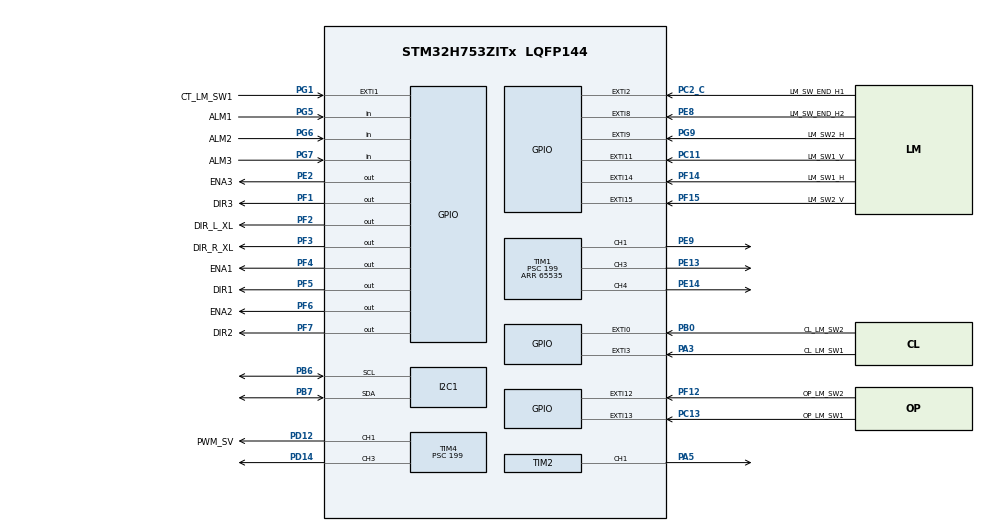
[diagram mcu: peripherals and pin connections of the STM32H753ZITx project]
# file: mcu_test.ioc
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CORTEX_M7.CPU_DCache=Disabled
CORTEX_M7.CPU_ICache=Disabled
CORTEX_M7.MPU_Control=__NULL
CORTEX_M7.default_mode_Activation=1
I2C1.Timing=0x10C0ECFF
Mcu.Family=STM32H7
Mcu.Name=STM32H753ZITx
Mcu.Package=LQFP144
NVIC.EXTI0_IRQn=true\:0\:0\:false\:false\:true\:true\:true\:true
NVIC.EXTI15_10_IRQn=true\:0\:0\:false\:false\:true\:true\:true\:true
NVIC.EXTI1_IRQn=true\:0\:0\:false\:false\:true\:true\:true\:true
NVIC.EXTI2_IRQn=true\:0\:0\:false\:false\:true\:true\:true\:true
NVIC.EXTI3_IRQn=true\:0\:0\:false\:false\:true\:true\:true\:true
NVIC.EXTI9_5_IRQn=true\:0\:0\:false\:false\:true\:true\:true\:true
NVIC.PriorityGroup=NVIC_PRIORITYGROUP_4
NVIC.TIM1_UP_IRQn=true\:0\:0\:false\:false\:true\:true\:true\:true
PA3.GPIO_Label=CL_LM_SW1
PA3.GPIO_ModeDefaultEXTI=GPIO_MODE_IT_RISING_FALLING
PA3.GPIO_PuPd=GPIO_PULLUP
PA3.Signal=GPXTI3
PA5.GPIO_ModeDefaultPP=GPIO_MODE_AF_PP
PA5.GPIO_PuPd=GPIO_PULLDOWN
PA5.Signal=S_TIM2_CH1_ETR
PB0.GPIO_Label=CL_LM_SW2
PB0.GPIO_ModeDefaultEXTI=GPIO_MODE_IT_RISING_FALLING
PB0.GPIO_PuPd=GPIO_PULLUP
PB0.Signal=GPXTI0
PB6.GPIO_Mode=GPIO_MODE_AF_OD
PB6.GPIO_Pu=GPIO_PULLUP
PB6.Mode=I2C
PB6.Signal=I2C1_SCL
PB7.GPIO_Mode=GPIO_MODE_AF_OD
PB7.GPIO_Pu=GPIO_PULLUP
PB7.Mode=I2C
PB7.Signal=I2C1_SDA
PC11.GPIO_Label=LM_SW1_V
PC11.GPIO_ModeDefaultEXTI=GPIO_MODE_IT_RISING_FALLING
PC11.GPIO_PuPd=GPIO_PULLUP
PC11.Signal=GPXTI11
PC13.GPIO_Label=OP_LM_SW1
PC13.GPIO_ModeDefaultEXTI=GPIO_MODE_IT_RISING_FALLING
PC13.GPIO_PuPd=GPIO_PULLUP
PC13.Signal=GPXTI13
PC14-OSC32_IN\ (OSC32_IN).Signal=RCC_OSC32_IN
PC15-OSC32_OUT\ (OSC32_OUT).Signal=RCC_OSC32_OUT
PC2_C.GPIO_Label=LM_SW_END_H1
PC2_C.GPIO_ModeDefaultEXTI=GPIO_MODE_IT_RISING_FALLING
PC2_C.GPIO_PuPd=GPIO_PULLUP
PC2_C.Signal=GPXTI2
PD12.GPIO_Label=PWM_SV
PD12.GPIO_PuPd=GPIO_PULLDOWN
PD12.Signal=S_TIM4_CH1
PD14.GPIO_PuPd=GPIO_PULLDOWN
PD14.Signal=S_TIM4_CH3
PD8.GPIO_Label=STLINK_RX
PD8.Signal=USART3_TX
PD9.GPIO_Label=STLINK_TX
PD9.Signal=USART3_RX
PE13.Signal=S_TIM1_CH3
PE14.Signal=S_TIM1_CH4
PE2.GPIO_Label=ENA3
PE2.PinState=GPIO_PIN_SET
PE2.Signal=GPIO_Output
PE8.GPIO_Label=LM_SW_END_H2
PE8.GPIO_ModeDefaultEXTI=GPIO_MODE_IT_RISING_FALLING
PE8.GPIO_PuPd=GPIO_PULLUP
PE8.Signal=GPXTI8
PE9.Signal=S_TIM1_CH1
PF1.GPIO_Label=DIR3
PF1.Signal=GPIO_Output
PF12.GPIO_Label=OP_LM_SW2
PF12.GPIO_ModeDefaultEXTI=GPIO_MODE_IT_RISING_FALLING
PF12.GPIO_PuPd=GPIO_PULLUP
PF12.Signal=GPXTI12
PF14.GPIO_Label=LM_SW1_H
PF14.GPIO_ModeDefaultEXTI=GPIO_MODE_IT_RISING_FALLING
PF14.GPIO_PuPd=GPIO_PULLUP
PF14.Signal=GPXTI14
PF15.GPIO_Label=LM_SW2_V
PF15.GPIO_ModeDefaultEXTI=GPIO_MODE_IT_RISING_FALLING
PF15.GPIO_PuPd=GPIO_PULLUP
PF15.Signal=GPXTI15
PF2.GPIO_Label=DIR_L_XL
PF2.GPIO_ModeDefaultOutputPP=GPIO_MODE_OUTPUT_PP
PF2.GPIO_PuPd=GPIO_NOPULL
PF2.Signal=GPIO_Output
PF3.GPIO_Label=DIR_R_XL
PF3.GPIO_ModeDefaultOutputPP=GPIO_MODE_OUTPUT_PP
PF3.GPIO_PuPd=GPIO_NOPULL
PF3.PinState=GPIO_PIN_RESET
PF3.Signal=GPIO_Output
PF4.GPIO_Label=ENA1
PF4.GPIO_ModeDefaultOutputPP=GPIO_MODE_OUTPUT_PP
PF4.PinState=GPIO_PIN_SET
PF4.Signal=GPIO_Output
PF5.GPIO_Label=DIR1
PF5.Signal=GPIO_Output
PF6.GPIO_Label=ENA2
PF6.PinState=GPIO_PIN_SET
PF6.Signal=GPIO_Output
PF7.GPIO_Label=DIR2
PF7.PinState=GPIO_PIN_RESET
PF7.Signal=GPIO_Output
PG1.GPIO_Label=CT_LM_SW1
PG1.GPIO_ModeDefaultEXTI=GPIO_MODE_IT_RISING_FALLING
PG1.GPIO_PuPd=GPIO_PULLUP
PG1.Signal=GPXTI1
PG5.GPIO_Label=ALM1
PG5.GPIO_PuPd=GPIO_PULLUP
PG5.Signal=GPIO_Input
PG6.GPIO_Label=ALM2
PG6.GPIO_PuPd=GPIO_PULLUP
PG6.Signal=GPIO_Input
PG7.GPIO_Label=ALM3
PG7.GPIO_PuPd=GPIO_PULLUP
PG7.Signal=GPIO_Input
PG9.GPIO_Label=LM_SW2_H
PG9.GPIO_ModeDefaultEXTI=GPIO_MODE_IT_RISING_FALLING
PG9.GPIO_PuPd=GPIO_PULLUP
PG9.Signal=GPXTI9
PH0-OSC_IN\ (PH0).Signal=RCC_OSC_IN
PH1-OSC_OUT\ (PH1).Signal=RCC_OSC_OUT
ProjectManager.HeapSize=0x200
ProjectManager.StackSize=0x400
ProjectManager.TargetToolchain=CMake
RCC.ADCFreq_Value=129000000
RCC.APB1Freq_Value=100000000
RCC.APB2Freq_Value=100000000
RCC.APB3Freq_Value=100000000
RCC.APB4Freq_Value=100000000
RCC.CortexFreq_Value=400000000
RCC.D1PPRE=RCC_APB3_DIV2
RCC.D2PPRE1=RCC_APB1_DIV2
RCC.D2PPRE2=RCC_APB2_DIV2
RCC.D3PPRE=RCC_APB4_DIV2
RCC.DIVM1=8
RCC.DIVN1=100
RCC.DIVQ1=4
RCC.HCLKFreq_Value=200000000
RCC.HPRE=RCC_HCLK_DIV2
RCC.HSE_VALUE=8000000
RCC.PLLFRACN=0
RCC.PWR_Regulator_Voltage_Scale=PWR_REGULATOR_VOLTAGE_SCALE1
RCC.SYSCLKFreq_VALUE=400000000
RCC.SYSCLKSource=RCC_SYSCLKSOURCE_PLLCLK
RCC.USBFreq_Value=200000000
SH.S_TIM1_CH1.0=TIM1_CH1,PWM Generation1 CH1
SH.S_TIM1_CH3.0=TIM1_CH3,PWM Generation3 CH3
SH.S_TIM1_CH4.0=TIM1_CH4,PWM Generation4 CH4
SH.S_TIM2_CH1_ETR.0=TIM2_CH1,PWM Generation1 CH1
SH.S_TIM4_CH1.0=TIM4_CH1,PWM Generation1 CH1
SH.S_TIM4_CH3.0=TIM4_CH3,PWM Generation3 CH3
TIM1.Channel-PWM\ Generation1\ CH1=TIM_CHANNEL_1
TIM1.Channel-PWM\ Generation3\ CH3=TIM_CHANNEL_3
TIM1.Channel-PWM\ Generation4\ CH4=TIM_CHANNEL_4
TIM1.Period=65535
TIM1.Prescaler=199
TIM2.Channel-PWM\ Generation1\ CH1=TIM_CHANNEL_1
TIM2.Period=3002
TIM2.Prescaler=199
TIM4.Channel-PWM\ Generation1\ CH1=TIM_CHANNEL_1
TIM4.Channel-PWM\ Generation3\ CH3=TIM_CHANNEL_3
TIM4.Period=3002
TIM4.Prescaler=199
TIM4.Pulse-PWM\ Generation1\ CH1=1900
VP_MEMORYMAP_VS_MEMORYMAP.Mode=CurAppReg
VP_TIM1_VS_ClockSourceINT.Mode=Internal
VP_TIM2_VS_ClockSourceINT.Mode=Internal
VP_TIM4_VS_ClockSourceINT.Mode=Internal
board=NUCLEO-H753ZI

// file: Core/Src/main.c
/* USER CODE BEGIN Header */
/**
  ******************************************************************************
  * @file           : main.c
  * @brief          : Main program body
  ******************************************************************************
  * @attention
  *
  * Copyright (c) 2026 STMicroelectronics.
  * All rights reserved.
  *
  * This software is licensed under terms that can be found in the LICENSE file
  * in the root directory of this software component.
  * If no LICENSE file comes with this software, it is provided AS-IS.
  *
  ******************************************************************************
  */
/* USER CODE END Header */
#include "main.h"

/* USER CODE BEGIN Includes */
#include "app.h"
/* USER CODE END Includes */

I2C_HandleTypeDef hi2c1;

TIM_HandleTypeDef htim1;
TIM_HandleTypeDef htim2;
TIM_HandleTypeDef htim4;

void SystemClock_Config(void);
static void MX_GPIO_Init(void);
static void MX_TIM4_Init(void);
static void MX_TIM1_Init(void);
static void MX_TIM2_Init(void);
static void MX_I2C1_Init(void);

int main(void)
{

  /* MCU Configuration--------------------------------------------------------*/

  /* Reset of all peripherals, Initializes the Flash interface and the Systick. */
  HAL_Init();

  /* Configure the system clock */
  SystemClock_Config();

  /* Initialize all configured peripherals */
  MX_GPIO_Init();
  MX_TIM4_Init();
  MX_TIM1_Init();
  MX_TIM2_Init();
  MX_I2C1_Init();
  /* USER CODE BEGIN 2 */
  App_Init();
  /* USER CODE END 2 */

  /* Infinite loop */
  while (1)
  {

    /* USER CODE BEGIN 3 */
    App_Poll();
  }
  /* USER CODE END 3 */
}

void SystemClock_Config(void)
{
  RCC_OscInitTypeDef RCC_OscInitStruct = {0};
  RCC_ClkInitTypeDef RCC_ClkInitStruct = {0};

  /** Supply configuration update enable
  */
  HAL_PWREx_ConfigSupply(PWR_LDO_SUPPLY);

  /** Configure the main internal regulator output voltage
  */
  __HAL_PWR_VOLTAGESCALING_CONFIG(PWR_REGULATOR_VOLTAGE_SCALE1);

  while(!__HAL_PWR_GET_FLAG(PWR_FLAG_VOSRDY)) {}

  /** Initializes the RCC Oscillators according to the specified parameters
  * in the RCC_OscInitTypeDef structure.
  */
  RCC_OscInitStruct.OscillatorType = RCC_OSCILLATORTYPE_HSI;
  RCC_OscInitStruct.HSIState = RCC_HSI_DIV1;
  RCC_OscInitStruct.HSICalibrationValue = RCC_HSICALIBRATION_DEFAULT;
  RCC_OscInitStruct.PLL.PLLState = RCC_PLL_ON;
  RCC_OscInitStruct.PLL.PLLSource = RCC_PLLSOURCE_HSI;
  RCC_OscInitStruct.PLL.PLLM = 8;
  RCC_OscInitStruct.PLL.PLLN = 100;
  RCC_OscInitStruct.PLL.PLLP = 2;
  RCC_OscInitStruct.PLL.PLLQ = 4;
  RCC_OscInitStruct.PLL.PLLR = 2;
  RCC_OscInitStruct.PLL.PLLRGE = RCC_PLL1VCIRANGE_3;
  RCC_OscInitStruct.PLL.PLLVCOSEL = RCC_PLL1VCOWIDE;
  RCC_OscInitStruct.PLL.PLLFRACN = 0;
  if (HAL_RCC_OscConfig(&RCC_OscInitStruct) != HAL_OK)
  {
    Error_Handler();
  }

  /** Initializes the CPU, AHB and APB buses clocks
  */
  RCC_ClkInitStruct.ClockType = RCC_CLOCKTYPE_HCLK|RCC_CLOCKTYPE_SYSCLK
                              |RCC_CLOCKTYPE_PCLK1|RCC_CLOCKTYPE_PCLK2
                              |RCC_CLOCKTYPE_D3PCLK1|RCC_CLOCKTYPE_D1PCLK1;
  RCC_ClkInitStruct.SYSCLKSource = RCC_SYSCLKSOURCE_PLLCLK;
  RCC_ClkInitStruct.SYSCLKDivider = RCC_SYSCLK_DIV1;
  RCC_ClkInitStruct.AHBCLKDivider = RCC_HCLK_DIV2;
  RCC_ClkInitStruct.APB3CLKDivider = RCC_APB3_DIV2;
  RCC_ClkInitStruct.APB1CLKDivider = RCC_APB1_DIV2;
  RCC_ClkInitStruct.APB2CLKDivider = RCC_APB2_DIV2;
  RCC_ClkInitStruct.APB4CLKDivider = RCC_APB4_DIV2;

  if (HAL_RCC_ClockConfig(&RCC_ClkInitStruct, FLASH_LATENCY_2) != HAL_OK)
  {
    Error_Handler();
  }
}

static void MX_I2C1_Init(void)
{

  hi2c1.Instance = I2C1;
  hi2c1.Init.Timing = 0x10C0ECFF;
  hi2c1.Init.OwnAddress1 = 0;
  hi2c1.Init.AddressingMode = I2C_ADDRESSINGMODE_7BIT;
  hi2c1.Init.DualAddressMode = I2C_DUALADDRESS_DISABLE;
  hi2c1.Init.OwnAddress2 = 0;
  hi2c1.Init.OwnAddress2Masks = I2C_OA2_NOMASK;
  hi2c1.Init.GeneralCallMode = I2C_GENERALCALL_DISABLE;
  hi2c1.Init.NoStretchMode = I2C_NOSTRETCH_DISABLE;
  if (HAL_I2C_Init(&hi2c1) != HAL_OK)
  {
    Error_Handler();
  }

  /** Configure Analogue filter
  */
  if (HAL_I2CEx_ConfigAnalogFilter(&hi2c1, I2C_ANALOGFILTER_ENABLE) != HAL_OK)
  {
    Error_Handler();
  }

  /** Configure Digital filter
  */
  if (HAL_I2CEx_ConfigDigitalFilter(&hi2c1, 0) != HAL_OK)
  {
    Error_Handler();
  }

}

static void MX_TIM1_Init(void)
{

  TIM_ClockConfigTypeDef sClockSourceConfig = {0};
  TIM_MasterConfigTypeDef sMasterConfig = {0};
  TIM_OC_InitTypeDef sConfigOC = {0};
  TIM_BreakDeadTimeConfigTypeDef sBreakDeadTimeConfig = {0};

  htim1.Instance = TIM1;
  htim1.Init.Prescaler = 199;
  htim1.Init.CounterMode = TIM_COUNTERMODE_UP;
  htim1.Init.Period = 65535;
  htim1.Init.ClockDivision = TIM_CLOCKDIVISION_DIV1;
  htim1.Init.RepetitionCounter = 0;
  htim1.Init.AutoReloadPreload = TIM_AUTORELOAD_PRELOAD_DISABLE;
  if (HAL_TIM_Base_Init(&htim1) != HAL_OK)
  {
    Error_Handler();
  }
  sClockSourceConfig.ClockSource = TIM_CLOCKSOURCE_INTERNAL;
  if (HAL_TIM_ConfigClockSource(&htim1, &sClockSourceConfig) != HAL_OK)
  {
    Error_Handler();
  }
  if (HAL_TIM_PWM_Init(&htim1) != HAL_OK)
  {
    Error_Handler();
  }
  sMasterConfig.MasterOutputTrigger = TIM_TRGO_RESET;
  sMasterConfig.MasterOutputTrigger2 = TIM_TRGO2_RESET;
  sMasterConfig.MasterSlaveMode = TIM_MASTERSLAVEMODE_DISABLE;
  if (HAL_TIMEx_MasterConfigSynchronization(&htim1, &sMasterConfig) != HAL_OK)
  {
    Error_Handler();
  }
  sConfigOC.OCMode = TIM_OCMODE_PWM1;
  sConfigOC.Pulse = 0;
  sConfigOC.OCPolarity = TIM_OCPOLARITY_HIGH;
  sConfigOC.OCNPolarity = TIM_OCNPOLARITY_HIGH;
  sConfigOC.OCFastMode = TIM_OCFAST_DISABLE;
  sConfigOC.OCIdleState = TIM_OCIDLESTATE_RESET;
  sConfigOC.OCNIdleState = TIM_OCNIDLESTATE_RESET;
  if (HAL_TIM_PWM_ConfigChannel(&htim1, &sConfigOC, TIM_CHANNEL_1) != HAL_OK)
  {
    Error_Handler();
  }
  if (HAL_TIM_PWM_ConfigChannel(&htim1, &sConfigOC, TIM_CHANNEL_3) != HAL_OK)
  {
    Error_Handler();
  }
  if (HAL_TIM_PWM_ConfigChannel(&htim1, &sConfigOC, TIM_CHANNEL_4) != HAL_OK)
  {
    Error_Handler();
  }
  sBreakDeadTimeConfig.OffStateRunMode = TIM_OSSR_DISABLE;
  sBreakDeadTimeConfig.OffStateIDLEMode = TIM_OSSI_DISABLE;
  sBreakDeadTimeConfig.LockLevel = TIM_LOCKLEVEL_OFF;
  sBreakDeadTimeConfig.DeadTime = 0;
  sBreakDeadTimeConfig.BreakState = TIM_BREAK_DISABLE;
  sBreakDeadTimeConfig.BreakPolarity = TIM_BREAKPOLARITY_HIGH;
  sBreakDeadTimeConfig.BreakFilter = 0;
  sBreakDeadTimeConfig.Break2State = TIM_BREAK2_DISABLE;
  sBreakDeadTimeConfig.Break2Polarity = TIM_BREAK2POLARITY_HIGH;
  sBreakDeadTimeConfig.Break2Filter = 0;
  sBreakDeadTimeConfig.AutomaticOutput = TIM_AUTOMATICOUTPUT_DISABLE;
  if (HAL_TIMEx_ConfigBreakDeadTime(&htim1, &sBreakDeadTimeConfig) != HAL_OK)
  {
    Error_Handler();
  }
  HAL_TIM_MspPostInit(&htim1);

}

static void MX_TIM2_Init(void)
{

  TIM_ClockConfigTypeDef sClockSourceConfig = {0};
  TIM_MasterConfigTypeDef sMasterConfig = {0};
  TIM_OC_InitTypeDef sConfigOC = {0};

  htim2.Instance = TIM2;
  htim2.Init.Prescaler = 199;
  htim2.Init.CounterMode = TIM_COUNTERMODE_UP;
  htim2.Init.Period = 3002;
  htim2.Init.ClockDivision = TIM_CLOCKDIVISION_DIV1;
  htim2.Init.AutoReloadPreload = TIM_AUTORELOAD_PRELOAD_DISABLE;
  if (HAL_TIM_Base_Init(&htim2) != HAL_OK)
  {
    Error_Handler();
  }
  sClockSourceConfig.ClockSource = TIM_CLOCKSOURCE_INTERNAL;
  if (HAL_TIM_ConfigClockSource(&htim2, &sClockSourceConfig) != HAL_OK)
  {
    Error_Handler();
  }
  if (HAL_TIM_PWM_Init(&htim2) != HAL_OK)
  {
    Error_Handler();
  }
  sMasterConfig.MasterOutputTrigger = TIM_TRGO_RESET;
  sMasterConfig.MasterSlaveMode = TIM_MASTERSLAVEMODE_DISABLE;
  if (HAL_TIMEx_MasterConfigSynchronization(&htim2, &sMasterConfig) != HAL_OK)
  {
    Error_Handler();
  }
  sConfigOC.OCMode = TIM_OCMODE_PWM1;
  sConfigOC.Pulse = 0;
  sConfigOC.OCPolarity = TIM_OCPOLARITY_HIGH;
  sConfigOC.OCFastMode = TIM_OCFAST_DISABLE;
  if (HAL_TIM_PWM_ConfigChannel(&htim2, &sConfigOC, TIM_CHANNEL_1) != HAL_OK)
  {
    Error_Handler();
  }
  HAL_TIM_MspPostInit(&htim2);

}

static void MX_TIM4_Init(void)
{

  TIM_ClockConfigTypeDef sClockSourceConfig = {0};
  TIM_MasterConfigTypeDef sMasterConfig = {0};
  TIM_OC_InitTypeDef sConfigOC = {0};

  htim4.Instance = TIM4;
  htim4.Init.Prescaler = 199;
  htim4.Init.CounterMode = TIM_COUNTERMODE_UP;
  htim4.Init.Period = 3002;
  htim4.Init.ClockDivision = TIM_CLOCKDIVISION_DIV1;
  htim4.Init.AutoReloadPreload = TIM_AUTORELOAD_PRELOAD_DISABLE;
  if (HAL_TIM_Base_Init(&htim4) != HAL_OK)
  {
    Error_Handler();
  }
  sClockSourceConfig.ClockSource = TIM_CLOCKSOURCE_INTERNAL;
  if (HAL_TIM_ConfigClockSource(&htim4, &sClockSourceConfig) != HAL_OK)
  {
    Error_Handler();
  }
  if (HAL_TIM_PWM_Init(&htim4) != HAL_OK)
  {
    Error_Handler();
  }
  sMasterConfig.MasterOutputTrigger = TIM_TRGO_RESET;
  sMasterConfig.MasterSlaveMode = TIM_MASTERSLAVEMODE_DISABLE;
  if (HAL_TIMEx_MasterConfigSynchronization(&htim4, &sMasterConfig) != HAL_OK)
  {
    Error_Handler();
  }
  sConfigOC.OCMode = TIM_OCMODE_PWM1;
  sConfigOC.Pulse = 1900;
  sConfigOC.OCPolarity = TIM_OCPOLARITY_HIGH;
  sConfigOC.OCFastMode = TIM_OCFAST_DISABLE;
  if (HAL_TIM_PWM_ConfigChannel(&htim4, &sConfigOC, TIM_CHANNEL_1) != HAL_OK)
  {
    Error_Handler();
  }
  sConfigOC.Pulse = 0;
  if (HAL_TIM_PWM_ConfigChannel(&htim4, &sConfigOC, TIM_CHANNEL_3) != HAL_OK)
  {
    Error_Handler();
  }
  HAL_TIM_MspPostInit(&htim4);

}

static void MX_GPIO_Init(void)
{
  GPIO_InitTypeDef GPIO_InitStruct = {0};

  /* GPIO Ports Clock Enable */
  __HAL_RCC_GPIOE_CLK_ENABLE();
  __HAL_RCC_GPIOC_CLK_ENABLE();
  __HAL_RCC_GPIOF_CLK_ENABLE();
  __HAL_RCC_GPIOH_CLK_ENABLE();
  __HAL_RCC_GPIOA_CLK_ENABLE();
  __HAL_RCC_GPIOB_CLK_ENABLE();
  __HAL_RCC_GPIOG_CLK_ENABLE();
  __HAL_RCC_GPIOD_CLK_ENABLE();

  /*Configure GPIO pin Output Level */
  HAL_GPIO_WritePin(ENA3_GPIO_Port, ENA3_Pin, GPIO_PIN_SET);

  /*Configure GPIO pin Output Level */
  HAL_GPIO_WritePin(GPIOF, DIR3_Pin|DIR_L_XL_Pin|DIR_R_XL_Pin|DIR1_Pin
                          |DIR2_Pin, GPIO_PIN_RESET);

  /*Configure GPIO pin Output Level */
  HAL_GPIO_WritePin(GPIOF, ENA1_Pin|ENA2_Pin, GPIO_PIN_SET);

  /*Configure GPIO pin : ENA3_Pin */
  GPIO_InitStruct.Pin = ENA3_Pin;
  GPIO_InitStruct.Mode = GPIO_MODE_OUTPUT_PP;
  GPIO_InitStruct.Pull = GPIO_NOPULL;
  GPIO_InitStruct.Speed = GPIO_SPEED_FREQ_LOW;
  HAL_GPIO_Init(ENA3_GPIO_Port, &GPIO_InitStruct);

  /*Configure GPIO pins : OP_LM_SW1_Pin LM_SW_END_H1_Pin LM_SW1_V_Pin */
  GPIO_InitStruct.Pin = OP_LM_SW1_Pin|LM_SW_END_H1_Pin|LM_SW1_V_Pin;
  GPIO_InitStruct.Mode = GPIO_MODE_IT_RISING_FALLING;
  GPIO_InitStruct.Pull = GPIO_PULLUP;
  HAL_GPIO_Init(GPIOC, &GPIO_InitStruct);

  /*Configure GPIO pins : DIR3_Pin DIR_L_XL_Pin DIR_R_XL_Pin ENA1_Pin
                           DIR1_Pin ENA2_Pin DIR2_Pin */
  GPIO_InitStruct.Pin = DIR3_Pin|DIR_L_XL_Pin|DIR_R_XL_Pin|ENA1_Pin
                          |DIR1_Pin|ENA2_Pin|DIR2_Pin;
  GPIO_InitStruct.Mode = GPIO_MODE_OUTPUT_PP;
  GPIO_InitStruct.Pull = GPIO_NOPULL;
  GPIO_InitStruct.Speed = GPIO_SPEED_FREQ_LOW;
  HAL_GPIO_Init(GPIOF, &GPIO_InitStruct);

  /*Configure GPIO pin : CL_LM_SW1_Pin */
  GPIO_InitStruct.Pin = CL_LM_SW1_Pin;
  GPIO_InitStruct.Mode = GPIO_MODE_IT_RISING_FALLING;
  GPIO_InitStruct.Pull = GPIO_PULLUP;
  HAL_GPIO_Init(CL_LM_SW1_GPIO_Port, &GPIO_InitStruct);

  /*Configure GPIO pin : CL_LM_SW2_Pin */
  GPIO_InitStruct.Pin = CL_LM_SW2_Pin;
  GPIO_InitStruct.Mode = GPIO_MODE_IT_RISING_FALLING;
  GPIO_InitStruct.Pull = GPIO_PULLUP;
  HAL_GPIO_Init(CL_LM_SW2_GPIO_Port, &GPIO_InitStruct);

  /*Configure GPIO pins : OP_LM_SW2_Pin LM_SW1_H_Pin LM_SW2_V_Pin */
  GPIO_InitStruct.Pin = OP_LM_SW2_Pin|LM_SW1_H_Pin|LM_SW2_V_Pin;
  GPIO_InitStruct.Mode = GPIO_MODE_IT_RISING_FALLING;
  GPIO_InitStruct.Pull = GPIO_PULLUP;
  HAL_GPIO_Init(GPIOF, &GPIO_InitStruct);

  /*Configure GPIO pins : CT_LM_SW1_Pin LM_SW2_H_Pin */
  GPIO_InitStruct.Pin = CT_LM_SW1_Pin|LM_SW2_H_Pin;
  GPIO_InitStruct.Mode = GPIO_MODE_IT_RISING_FALLING;
  GPIO_InitStruct.Pull = GPIO_PULLUP;
  HAL_GPIO_Init(GPIOG, &GPIO_InitStruct);

  /*Configure GPIO pin : LM_SW_END_H2_Pin */
  GPIO_InitStruct.Pin = LM_SW_END_H2_Pin;
  GPIO_InitStruct.Mode = GPIO_MODE_IT_RISING_FALLING;
  GPIO_InitStruct.Pull = GPIO_PULLUP;
  HAL_GPIO_Init(LM_SW_END_H2_GPIO_Port, &GPIO_InitStruct);

  /*Configure GPIO pins : STLINK_RX_Pin STLINK_TX_Pin */
  GPIO_InitStruct.Pin = STLINK_RX_Pin|STLINK_TX_Pin;
  GPIO_InitStruct.Mode = GPIO_MODE_AF_PP;
  GPIO_InitStruct.Pull = GPIO_NOPULL;
  GPIO_InitStruct.Speed = GPIO_SPEED_FREQ_LOW;
  GPIO_InitStruct.Alternate = GPIO_AF7_USART3;
  HAL_GPIO_Init(GPIOD, &GPIO_InitStruct);

  /*Configure GPIO pins : ALM1_Pin ALM2_Pin ALM3_Pin */
  GPIO_InitStruct.Pin = ALM1_Pin|ALM2_Pin|ALM3_Pin;
  GPIO_InitStruct.Mode = GPIO_MODE_INPUT;
  GPIO_InitStruct.Pull = GPIO_PULLUP;
  HAL_GPIO_Init(GPIOG, &GPIO_InitStruct);

  /* EXTI interrupt init*/
  HAL_NVIC_SetPriority(CL_LM_SW2_EXTI_IRQn, 0, 0);
  HAL_NVIC_EnableIRQ(CL_LM_SW2_EXTI_IRQn);

  HAL_NVIC_SetPriority(CT_LM_SW1_EXTI_IRQn, 0, 0);
  HAL_NVIC_EnableIRQ(CT_LM_SW1_EXTI_IRQn);

  HAL_NVIC_SetPriority(LM_SW_END_H1_EXTI_IRQn, 0, 0);
  HAL_NVIC_EnableIRQ(LM_SW_END_H1_EXTI_IRQn);

  HAL_NVIC_SetPriority(CL_LM_SW1_EXTI_IRQn, 0, 0);
  HAL_NVIC_EnableIRQ(CL_LM_SW1_EXTI_IRQn);

  HAL_NVIC_SetPriority(LM_SW_END_H2_EXTI_IRQn, 0, 0);
  HAL_NVIC_EnableIRQ(LM_SW_END_H2_EXTI_IRQn);

  HAL_NVIC_SetPriority(LM_SW1_V_EXTI_IRQn, 0, 0);
  HAL_NVIC_EnableIRQ(LM_SW1_V_EXTI_IRQn);

}

void Error_Handler(void)
{
  __disable_irq();
  while (1)
  {
  }
}
